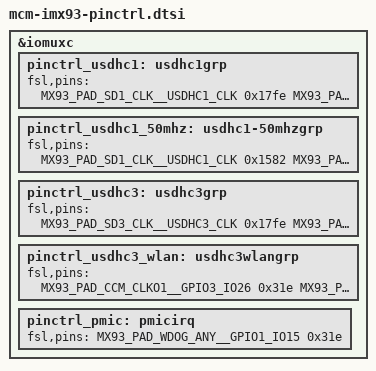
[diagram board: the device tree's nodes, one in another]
// SPDX-License-Identifier: (GPL-2.0+ OR MIT)
/*
 * Copyright 2026 CompuLab Ltd.
 */

&iomuxc {






	pinctrl_usdhc1: usdhc1grp {
		fsl,pins = <
			MX93_PAD_SD1_CLK__USDHC1_CLK		0x17fe
			MX93_PAD_SD1_CMD__USDHC1_CMD		0x13fe
			MX93_PAD_SD1_DATA0__USDHC1_DATA0	0x13fe
			MX93_PAD_SD1_DATA1__USDHC1_DATA1	0x13fe
			MX93_PAD_SD1_DATA2__USDHC1_DATA2	0x13fe
			MX93_PAD_SD1_DATA3__USDHC1_DATA3	0x13fe
			MX93_PAD_SD1_DATA4__USDHC1_DATA4	0x13fe
			MX93_PAD_SD1_DATA5__USDHC1_DATA5	0x13fe
			MX93_PAD_SD1_DATA6__USDHC1_DATA6	0x13fe
			MX93_PAD_SD1_DATA7__USDHC1_DATA7	0x13fe
			MX93_PAD_SD1_STROBE__USDHC1_STROBE	0x17fe
		>;
	};

	/* need to config the SION for data and cmd pad, refer to ERR052021 */
	pinctrl_usdhc1_50mhz: usdhc1-50mhzgrp {
		fsl,pins = <
			MX93_PAD_SD1_CLK__USDHC1_CLK		0x1582
			MX93_PAD_SD1_CMD__USDHC1_CMD		0x40001382
			MX93_PAD_SD1_DATA0__USDHC1_DATA0	0x40001382
			MX93_PAD_SD1_DATA1__USDHC1_DATA1	0x40001382
			MX93_PAD_SD1_DATA2__USDHC1_DATA2	0x40001382
			MX93_PAD_SD1_DATA3__USDHC1_DATA3	0x40001382
			MX93_PAD_SD1_DATA4__USDHC1_DATA4	0x40001382
			MX93_PAD_SD1_DATA5__USDHC1_DATA5	0x40001382
			MX93_PAD_SD1_DATA6__USDHC1_DATA6	0x40001382
			MX93_PAD_SD1_DATA7__USDHC1_DATA7	0x40001382
			MX93_PAD_SD1_STROBE__USDHC1_STROBE	0x1582
		>;
	};

	/* need to config the SION for data and cmd pad, refer to ERR052021 */

	/* need to config the SION for data and cmd pad, refer to ERR052021 */




	pinctrl_usdhc3: usdhc3grp {
		fsl,pins = <
			MX93_PAD_SD3_CLK__USDHC3_CLK			0x17fe
			MX93_PAD_SD3_CMD__USDHC3_CMD			0x13fe
			MX93_PAD_SD3_DATA0__USDHC3_DATA0		0x13fe
			MX93_PAD_SD3_DATA1__USDHC3_DATA1        	0x13fe
			MX93_PAD_SD3_DATA2__USDHC3_DATA2        	0x13fe
			MX93_PAD_SD3_DATA3__USDHC3_DATA3        	0x13fe
		>;
	};



	pinctrl_usdhc3_wlan: usdhc3wlangrp {
		fsl,pins = <
			MX93_PAD_CCM_CLKO1__GPIO3_IO26			0x31e
			MX93_PAD_GPIO_IO07__GPIO2_IO07			0x31e
			/*MX93_PAD_GPIO_IO17__GPIO2_IO17			0x31e*/
		>;
	};




	pinctrl_pmic: pmicirq {
		fsl,pins = <
			MX93_PAD_WDOG_ANY__GPIO1_IO15	0x31e
		>;
	};


};
